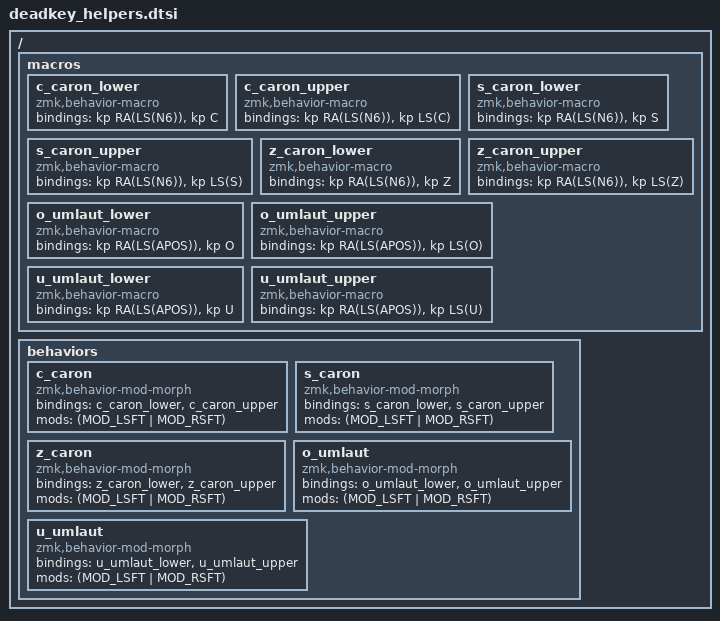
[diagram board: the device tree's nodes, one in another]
// Eurkey dead letter definitions

// Deadkey helpers for Slovenian/Czech characters
// Usage: Add this to your keymap's behaviors section

/ {
	macros {
		// Č/č - c with caron
		c_caron_lower: c_caron_lower {
			compatible = "zmk,behavior-macro";
			#binding-cells = <0>;
			bindings = <&kp RA(LS(N6)) &kp C>;
		};
		c_caron_upper: c_caron_upper {
			compatible = "zmk,behavior-macro";
			#binding-cells = <0>;
			bindings = <&kp RA(LS(N6)) &kp LS(C)>;
		};

		// Š/š - s with caron
		s_caron_lower: s_caron_lower {
			compatible = "zmk,behavior-macro";
			#binding-cells = <0>;
			bindings = <&kp RA(LS(N6)) &kp S>;
		};
		s_caron_upper: s_caron_upper {
			compatible = "zmk,behavior-macro";
			#binding-cells = <0>;
			bindings = <&kp RA(LS(N6)) &kp LS(S)>;
		};

		// Ž/ž - z with caron
		z_caron_lower: z_caron_lower {
			compatible = "zmk,behavior-macro";
			#binding-cells = <0>;
			bindings = <&kp RA(LS(N6)) &kp Z>;
		};
		z_caron_upper: z_caron_upper {
			compatible = "zmk,behavior-macro";
			#binding-cells = <0>;
			bindings = <&kp RA(LS(N6)) &kp LS(Z)>;
		};

		// Ö/ö - o with umlaut
		o_umlaut_lower: o_umlaut_lower {
			compatible = "zmk,behavior-macro";
			#binding-cells = <0>;
			bindings = <&kp RA(LS(APOS)) &kp O>;
		};
		o_umlaut_upper: o_umlaut_upper {
			compatible = "zmk,behavior-macro";
			#binding-cells = <0>;
			bindings = <&kp RA(LS(APOS)) &kp LS(O)>;
		};

		// Ü/ü - u with umlaut
		u_umlaut_lower: u_umlaut_lower {
			compatible = "zmk,behavior-macro";
			#binding-cells = <0>;
			bindings = <&kp RA(LS(APOS)) &kp U>;
		};
		u_umlaut_upper: u_umlaut_upper {
			compatible = "zmk,behavior-macro";
			#binding-cells = <0>;
			bindings = <&kp RA(LS(APOS)) &kp LS(U)>;
		};
	};

	behaviors {
		// Mod-morphs that switch between lower/upper case based on shift
		c_caron: c_caron {
			compatible = "zmk,behavior-mod-morph";
			#binding-cells = <0>;
			bindings = <&c_caron_lower>, <&c_caron_upper>;
			mods = <(MOD_LSFT | MOD_RSFT)>;
		};

		s_caron: s_caron {
			compatible = "zmk,behavior-mod-morph";
			#binding-cells = <0>;
			bindings = <&s_caron_lower>, <&s_caron_upper>;
			mods = <(MOD_LSFT | MOD_RSFT)>;
		};

		z_caron: z_caron {
			compatible = "zmk,behavior-mod-morph";
			#binding-cells = <0>;
			bindings = <&z_caron_lower>, <&z_caron_upper>;
			mods = <(MOD_LSFT | MOD_RSFT)>;
		};

		o_umlaut: o_umlaut {
			compatible = "zmk,behavior-mod-morph";
			#binding-cells = <0>;
			bindings = <&o_umlaut_lower>, <&o_umlaut_upper>;
			mods = <(MOD_LSFT | MOD_RSFT)>;
		};

		u_umlaut: u_umlaut {
			compatible = "zmk,behavior-mod-morph";
			#binding-cells = <0>;
			bindings = <&u_umlaut_lower>, <&u_umlaut_upper>;
			mods = <(MOD_LSFT | MOD_RSFT)>;
		};
	};
};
